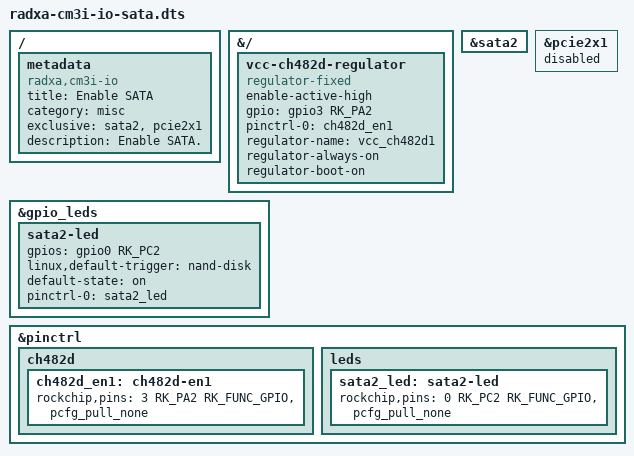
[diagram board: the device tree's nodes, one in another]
/dts-v1/;
/plugin/;

#include <dt-bindings/gpio/gpio.h>
#include <dt-bindings/pinctrl/rockchip.h>

/ {
	metadata {
		title = "Enable SATA";
		compatible = "radxa,cm3i-io";
		category = "misc";
		exclusive = "sata2", "pcie2x1";
		description = "Enable SATA.";
	};
};

&{/} {
	vcc-ch482d-regulator {
		compatible = "regulator-fixed";
		enable-active-high;
		gpio = <&gpio3 RK_PA2 GPIO_ACTIVE_HIGH>;
		pinctrl-names = "default";
		pinctrl-0 = <&ch482d_en1>;
		regulator-name = "vcc_ch482d1";
		regulator-always-on;
		regulator-boot-on;
	};
};

&sata2 {
	status = "okay";
};

&gpio_leds {
	sata2-led {
		gpios = <&gpio0 RK_PC2 GPIO_ACTIVE_HIGH>;
		linux,default-trigger = "nand-disk";
		default-state = "on";
		pinctrl-0 = <&sata2_led>;
	};
};

&pcie2x1 {
	status = "disabled";
};

&pinctrl {
	ch482d {
		//pcie2.0 --> sata2
		ch482d_en1: ch482d-en1 {
			rockchip,pins = <3 RK_PA2 RK_FUNC_GPIO &pcfg_pull_none>;
		};
	};

	leds {
		sata2_led: sata2-led{
			rockchip,pins = <0 RK_PC2 RK_FUNC_GPIO &pcfg_pull_none>;
		};
	};
};
